# usb register map
Vendor: Texas Instruments
Peripheral module from a debugger description file (folder MSP432E4).
Registers are 8-bit, read-write, no defined reset value unless marked. A register's access mark holds for its fields unless they carry their own. Offsets are as the file gives them; lines under a group give offsets from that group; [hi:lo] are bit positions; {n}, {i} and the like mark numbered series; 'fields as' and 'values as' point back to an identical list; <NAME> marks a mode.

## USB0 — Univeral Serial Bus register offsets
0x00 USB_FADDR — USB Device Functional Address
  [6:0] USB_FADDR — Function Address
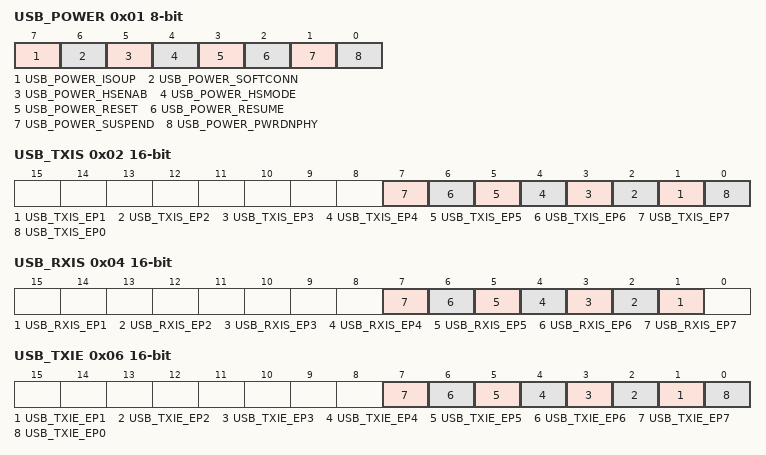
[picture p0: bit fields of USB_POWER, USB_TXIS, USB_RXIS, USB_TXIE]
0x01 USB_POWER
  [7] USB_POWER_ISOUP — Isochronous Update
  [6] USB_POWER_SOFTCONN — Soft Connect/Disconnect
  [5] USB_POWER_HSENAB — High Speed Enable
  [4] USB_POWER_HSMODE — High Speed Enable
  [3] USB_POWER_RESET — RESET Signaling
  [2] USB_POWER_RESUME — RESUME Signaling
  [1] USB_POWER_SUSPEND — SUSPEND Mode
  [0] USB_POWER_PWRDNPHY — Power Down PHY
0x02 USB_TXIS 16-bit ro — USB Transmit Interrupt Status
  [n] USB_TXIS_EP{n} (n=1..7) — TX Endpoint {n} Interrupt
  [0] USB_TXIS_EP0 — TX and RX Endpoint 0 Interrupt
0x04 USB_RXIS 16-bit ro — USB Receive Interrupt Status
  [n] USB_RXIS_EP{n} (n=1..7) — RX Endpoint {n} Interrupt
0x06 USB_TXIE 16-bit — USB Transmit Interrupt Enable
  [n] USB_TXIE_EP{n} (n=1..7) — TX Endpoint {n} Interrupt Enable
  [0] USB_TXIE_EP0 — TX and RX Endpoint 0 Interrupt Enable
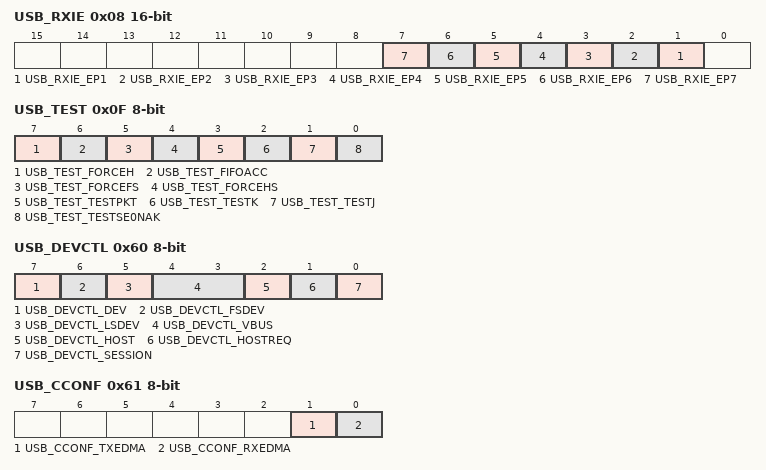
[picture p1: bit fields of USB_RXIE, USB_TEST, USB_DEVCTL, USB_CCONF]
0x08 USB_RXIE 16-bit — USB Receive Interrupt Enable
  [n] USB_RXIE_EP{n} (n=1..7) — RX Endpoint {n} Interrupt Enable
0x0A USB_IS ro — USB General Interrupt Status
  [7] USB_IS_VBUSERR — VBUS Error (OTG only)
  [6] USB_IS_SESREQ — SESSION REQUEST (OTG only)
  [5] USB_IS_DISCON — Session Disconnect (OTG only)
  [4] USB_IS_CONN — Session Connect
  [3] USB_IS_SOF — Start of Frame
  [2] USB_IS_BABBLE — Babble Detected
  [2] USB_IS_RESET — RESET Signaling Detected
  [1] USB_IS_RESUME — RESUME Signaling Detected
  [0] USB_IS_SUSPEND — SUSPEND Signaling Detected
0x0B USB_IE — USB Interrupt Enable
  [7] USB_IE_VBUSERR — Enable VBUS Error Interrupt (OTG only)
  [6] USB_IE_SESREQ — Enable Session Request (OTG only)
  [5] USB_IE_DISCON — Enable Disconnect Interrupt
  [4] USB_IE_CONN — Enable Connect Interrupt
  [3] USB_IE_SOF — Enable Start-of-Frame Interrupt
  [2] USB_IE_BABBLE — Enable Babble Interrupt
  [2] USB_IE_RESET — Enable RESET Interrupt
  [1] USB_IE_RESUME — Enable RESUME Interrupt
  [0] USB_IE_SUSPND — Enable SUSPEND Interrupt
0x0C USB_FRAME 16-bit ro — USB Frame Value
  [10:0] USB_FRAME — Frame Number
0x0E USB_EPIDX — USB Endpoint Index
  [3:0] USB_EPIDX_EPIDX — Endpoint Index
0x0F USB_TEST — USB Test Mode
  [7] USB_TEST_FORCEH — Force Host Mode
  [6] USB_TEST_FIFOACC — FIFO Access
  [5] USB_TEST_FORCEFS — Force Full-Speed Mode
  [4] USB_TEST_FORCEHS — Force High-Speed Mode
  [3] USB_TEST_TESTPKT — Test Packet Mode Enable
  [2] USB_TEST_TESTK — Test_K Mode Enable
  [1] USB_TEST_TESTJ — Test_J Mode Enable
  [0] USB_TEST_TESTSE0NAK — Test_SE0_NAK Test Mode Enable
{0x20+4i} USB_FIFO{i} 32-bit (i=0..7) — USB FIFO Endpoint {i}
  [31:0] USB_FIFO{i}_EPDATA — Endpoint Data
0x60 USB_DEVCTL — USB Device Control
  [7] USB_DEVCTL_DEV — Device Mode (OTG only)
  [6] USB_DEVCTL_FSDEV — Full-Speed Device Detected
  [5] USB_DEVCTL_LSDEV — Low-Speed Device Detected
  [4:3] USB_DEVCTL_VBUS — VBUS Level (OTG only)
    0=USB_DEVCTL_VBUS_NONE (Below SessionEnd); 1=USB_DEVCTL_VBUS_SEND (Above SessionEnd, below AValid); 2=USB_DEVCTL_VBUS_AVALID (Above AValid, below VBUSValid); 3=USB_DEVCTL_VBUS_VALID (Above VBUSValid)
  [2] USB_DEVCTL_HOST — Host Mode
  [1] USB_DEVCTL_HOSTREQ — Host Request (OTG only)
  [0] USB_DEVCTL_SESSION — Session Start/End (OTG only)
0x61 USB_CCONF — USB Common Configuration
  [1] USB_CCONF_TXEDMA — TX Early DMA Enable
  [0] USB_CCONF_RXEDMA — TX Early DMA Enable
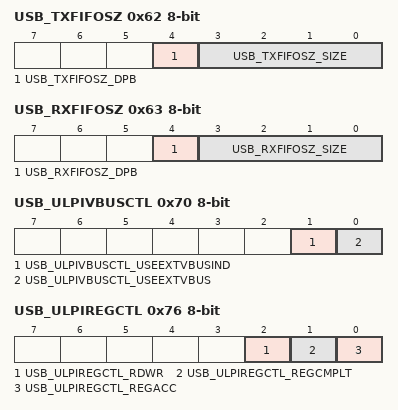
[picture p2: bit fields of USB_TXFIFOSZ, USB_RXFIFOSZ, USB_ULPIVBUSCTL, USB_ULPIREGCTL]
0x62 USB_TXFIFOSZ — USB Transmit Dynamic FIFO Sizing
  [4] USB_TXFIFOSZ_DPB — Double Packet Buffer Support
  [3:0] USB_TXFIFOSZ_SIZE — Max Packet Size
    0=8; 1=16; 2=32; 3=64; 4=128; 5=256; 6=512; 7=1024; 8=2048
0x63 USB_RXFIFOSZ — USB Receive Dynamic FIFO Sizing
  [4] USB_RXFIFOSZ_DPB — Double Packet Buffer Support
  [3:0] USB_RXFIFOSZ_SIZE — Max Packet Size
    0=8; 1=16; 2=32; 3=64; 4=128; 5=256; 6=512; 7=1024; 8=2048
0x64 USB_TXFIFOADD 16-bit — USB Transmit FIFO Start Address
  [8:0] USB_TXFIFOADD_ADDR — Transmit/Receive Start Address
0x66 USB_RXFIFOADD 16-bit — USB Receive FIFO Start Address
  [8:0] USB_RXFIFOADD_ADDR — Transmit/Receive Start Address
0x70 USB_ULPIVBUSCTL — USB ULPI VBUS Control
  [1] USB_ULPIVBUSCTL_USEEXTVBUSIND — Use External VBUS Indicator
  [0] USB_ULPIVBUSCTL_USEEXTVBUS — Use External VBUS
0x74 USB_ULPIREGDATA — USB ULPI Register Data
  [7:0] USB_ULPIREGDATA_REGDATA — Register Data
0x75 USB_ULPIREGADDR — USB ULPI Register Address
  [7:0] USB_ULPIREGADDR_ADDR — Register Address
0x76 USB_ULPIREGCTL — USB ULPI Register Control
  [2] USB_ULPIREGCTL_RDWR — Read/Write Control
  [1] USB_ULPIREGCTL_REGCMPLT — Register Access Complete
  [0] USB_ULPIREGCTL_REGACC — Initiate Register Access
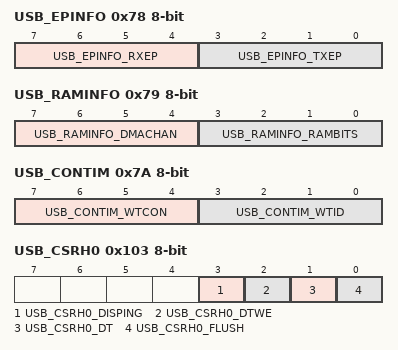
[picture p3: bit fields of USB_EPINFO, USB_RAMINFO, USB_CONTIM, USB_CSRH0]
0x78 USB_EPINFO ro — USB Endpoint Information
  [7:4] USB_EPINFO_RXEP — RX Endpoints
  [3:0] USB_EPINFO_TXEP — TX Endpoints
0x79 USB_RAMINFO ro — USB RAM Information
  [7:4] USB_RAMINFO_DMACHAN — DMA Channels
  [3:0] USB_RAMINFO_RAMBITS — RAM Address Bus Width
0x7A USB_CONTIM — USB Connect Timing
  [7:4] USB_CONTIM_WTCON — Connect Wait
  [3:0] USB_CONTIM_WTID — Wait ID
0x7B USB_VPLEN — USB OTG VBUS Pulse Timing
  [7:0] USB_VPLEN_VPLEN — VBUS Pulse Length
0x7C USB_HSEOF — USB High-Speed Last Transaction to End of Frame Timing
  [7:0] USB_HSEOF_HSEOFG — HIgh-Speed End-of-Frame Gap
0x7D USB_FSEOF — USB Full-Speed Last Transaction to End of Frame Timing
  [7:0] USB_FSEOF_FSEOFG — Full-Speed End-of-Frame Gap
0x7E USB_LSEOF — USB Low-Speed Last Transaction to End of Frame Timing
  [7:0] USB_LSEOF_LSEOFG — Low-Speed End-of-Frame Gap
{0x80+8i} USB_TXFUNCADDR{i} (i=0..7) — USB Transmit Functional Address Endpoint {i}
  [6:0] USB_TXFUNCADDR{i}_ADDR — Device Address
{0x82+8i} USB_TXHUBADDR{i} (i=0..7) — USB Transmit Hub Address Endpoint {i}
  [6:0] USB_TXHUBADDR{i}_ADDR — Hub Address
{0x83+8i} USB_TXHUBPORT{i} (i=0..7) — USB Transmit Hub Port Endpoint {i}
  [6:0] USB_TXHUBPORT{i}_PORT — Hub Port
{0x84+8i} USB_RXFUNCADDR{i} (i=1..7) — USB Receive Functional Address Endpoint {i}
  [6:0] USB_RXFUNCADDR{i}_ADDR — Device Address
{0x86+8i} USB_RXHUBADDR{i} (i=1..7) — USB Receive Hub Address Endpoint {i}
  [6:0] USB_RXHUBADDR{i}_ADDR — Hub Address
{0x87+8i} USB_RXHUBPORT{i} (i=1..7) — USB Receive Hub Port Endpoint {i}
  [6:0] USB_RXHUBPORT{i}_PORT — Hub Port
0x102 USB_CSRL0 wo — USB Control and Status Endpoint 0 Low
  [7] USB_CSRL0_NAKTO — NAK Timeout
  [7] USB_CSRL0_SETENDC — Setup End Clear
  [6] USB_CSRL0_STATUS — STATUS Packet
  [6] USB_CSRL0_RXRDYC — RXRDY Clear
  [5] USB_CSRL0_REQPKT — Request Packet
  [5] USB_CSRL0_STALL — Send Stall
  [4] USB_CSRL0_SETEND — Setup End
  [4] USB_CSRL0_ERROR — Error
  [3] USB_CSRL0_DATAEND — Data End
  [3] USB_CSRL0_SETUP — Setup Packet
  [2] USB_CSRL0_STALLED — Endpoint Stalled
  [1] USB_CSRL0_TXRDY — Transmit Packet Ready
  [0] USB_CSRL0_RXRDY — Receive Packet Ready
0x103 USB_CSRH0 wo — USB Control and Status Endpoint 0 High
  [3] USB_CSRH0_DISPING — PING Disable
  [2] USB_CSRH0_DTWE — Data Toggle Write Enable
  [1] USB_CSRH0_DT — Data Toggle
  [0] USB_CSRH0_FLUSH — Flush FIFO
0x108 USB_COUNT0 ro — USB Receive Byte Count Endpoint 0
  [6:0] USB_COUNT0_COUNT — FIFO Count
0x10A USB_TYPE0 — USB Type Endpoint 0
  [7:6] USB_TYPE0_SPEED — Operating Speed
    1=USB_TYPE0_SPEED_HIGH (High); 2=USB_TYPE0_SPEED_FULL (Full); 3=USB_TYPE0_SPEED_LOW (Low)
0x10B USB_NAKLMT — USB NAK Limit
  [4:0] USB_NAKLMT_NAKLMT — EP0 NAK Limit
{0x100+0x10*i} USB_TXMAXP{i} 16-bit (i=1..7) — USB Maximum Transmit Data Endpoint {i}
  [10:0] USB_TXMAXP{i}_MAXLOAD — Maximum Payload
0x112 USB_TXCSRL1 — USB Transmit Control and Status Endpoint 1 Low
  [7] USB_TXCSRL1_NAKTO — NAK Timeout
  [6] USB_TXCSRL1_CLRDT — Clear Data Toggle
  [5] USB_TXCSRL1_STALLED — Endpoint Stalled
  [4] USB_TXCSRL1_STALL — Send STALL
  [4] USB_TXCSRL1_SETUP — Setup Packet
  [3] USB_TXCSRL1_FLUSH — Flush FIFO
  [2] USB_TXCSRL1_ERROR — Error
  [2] USB_TXCSRL1_UNDRN — Underrun
  [1] USB_TXCSRL1_FIFONE — FIFO Not Empty
  [0] USB_TXCSRL1_TXRDY — Transmit Packet Ready
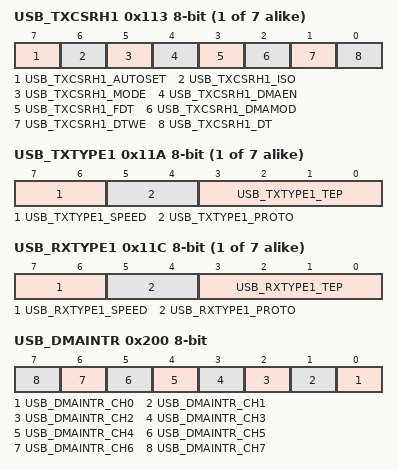
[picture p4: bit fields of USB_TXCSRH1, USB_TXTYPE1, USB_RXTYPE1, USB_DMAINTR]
{0x103+0x10*i} USB_TXCSRH{i} (i=1..7) — USB Transmit Control and Status Endpoint {i} High
  [7] USB_TXCSRH{i}_AUTOSET — Auto Set
  [6] USB_TXCSRH{i}_ISO — Isochronous Transfers
  [5] USB_TXCSRH{i}_MODE — Mode
  [4] USB_TXCSRH{i}_DMAEN — DMA Request Enable
  [3] USB_TXCSRH{i}_FDT — Force Data Toggle
  [2] USB_TXCSRH{i}_DMAMOD — DMA Request Mode
  [1] USB_TXCSRH{i}_DTWE — Data Toggle Write Enable
  [0] USB_TXCSRH{i}_DT — Data Toggle
{0x104+0x10*i} USB_RXMAXP{i} 16-bit (i=1..7) — USB Maximum Receive Data Endpoint {i}
  [10:0] USB_RXMAXP{i}_MAXLOAD — Maximum Payload
0x116 USB_RXCSRL1 — USB Receive Control and Status Endpoint 1 Low
  [7] USB_RXCSRL1_CLRDT — Clear Data Toggle
  [6] USB_RXCSRL1_STALLED — Endpoint Stalled
  [5] USB_RXCSRL1_STALL — Send STALL
  [5] USB_RXCSRL1_REQPKT — Request Packet
  [4] USB_RXCSRL1_FLUSH — Flush FIFO
  [3] USB_RXCSRL1_DATAERR — Data Error
  [3] USB_RXCSRL1_NAKTO — NAK Timeout
  [2] USB_RXCSRL1_OVER — Overrun
  [2] USB_RXCSRL1_ERROR — Error
  [1] USB_RXCSRL1_FULL — FIFO Full
  [0] USB_RXCSRL1_RXRDY — Receive Packet Ready
{0x107+0x10*i} USB_RXCSRH{i} (i=1..6) — USB Receive Control and Status Endpoint {i} High
  [7] USB_RXCSRH{i}_AUTOCL — Auto Clear
  [6] USB_RXCSRH{i}_AUTORQ — Auto Request
  [6] USB_RXCSRH{i}_ISO — Isochronous Transfers
  [5] USB_RXCSRH{i}_DMAEN — DMA Request Enable
  [4] USB_RXCSRH{i}_DISNYET — Disable NYET
  [4] USB_RXCSRH{i}_PIDERR — PID Error
  [3] USB_RXCSRH{i}_DMAMOD — DMA Request Mode
  [2] USB_RXCSRH{i}_DTWE — Data Toggle Write Enable
  [1] USB_RXCSRH{i}_DT — Data Toggle
  [0] USB_RXCSRH{i}_INCOMPRX — Incomplete RX Transmission Status
{0x108+0x10*i} USB_RXCOUNT{i} 16-bit ro (i=1..7) — USB Receive Byte Count Endpoint {i}
  [12:0] USB_RXCOUNT{i}_COUNT — Receive Packet Count
{0x10A+0x10*i} USB_TXTYPE{i} (i=1..7) — USB Host Transmit Configure Type Endpoint {i}
  [7:6] USB_TXTYPE{i}_SPEED — Operating Speed
    0=USB_TXTYPE{i}_SPEED_DFLT (Default); 1=USB_TXTYPE{i}_SPEED_HIGH (High); 2=USB_TXTYPE{i}_SPEED_FULL (Full); 3=USB_TXTYPE{i}_SPEED_LOW (Low)
  [5:4] USB_TXTYPE{i}_PROTO — Protocol
    0=USB_TXTYPE{i}_PROTO_CTRL (Control); 1=USB_TXTYPE{i}_PROTO_ISOC (Isochronous); 2=USB_TXTYPE{i}_PROTO_BULK (Bulk); 3=USB_TXTYPE{i}_PROTO_INT (Interrupt)
  [3:0] USB_TXTYPE{i}_TEP — Target Endpoint Number
0x11B USB_TXINTERVAL1 — USB Host Transmit Interval Endpoint 1
  [7:0] USB_TXINTERVAL1_TXPOLL_NAKLMT — TX Polling / NAK Limit
{0x10C+0x10*i} USB_RXTYPE{i} (i=1..7) — USB Host Configure Receive Type Endpoint {i}
  [7:6] USB_RXTYPE{i}_SPEED — Operating Speed
    0=USB_RXTYPE{i}_SPEED_DFLT (Default); 1=USB_RXTYPE{i}_SPEED_HIGH (High); 2=USB_RXTYPE{i}_SPEED_FULL (Full); 3=USB_RXTYPE{i}_SPEED_LOW (Low)
  [5:4] USB_RXTYPE{i}_PROTO — Protocol
    0=USB_RXTYPE{i}_PROTO_CTRL (Control); 1=USB_RXTYPE{i}_PROTO_ISOC (Isochronous); 2=USB_RXTYPE{i}_PROTO_BULK (Bulk); 3=USB_RXTYPE{i}_PROTO_INT (Interrupt)
  [3:0] USB_RXTYPE{i}_TEP — Target Endpoint Number
{0x10D+0x10*i} USB_RXINTERVAL{i} (i=1..7) — USB Host Receive Polling Interval Endpoint {i}
  [7:0] USB_RXINTERVAL{i}_TXPOLL_NAKLMT — RX Polling / NAK Limit
{0x102+0x10*i} USB_TXCSRL{i} (i=2..5) — USB Transmit Control and Status Endpoint {i} Low
  [7] USB_TXCSRL{i}_NAKTO — NAK Timeout
  [6] USB_TXCSRL{i}_CLRDT — Clear Data Toggle
  [5] USB_TXCSRL{i}_STALLED — Endpoint Stalled
  [4] USB_TXCSRL{i}_SETUP — Setup Packet
  [4] USB_TXCSRL{i}_STALL — Send STALL
  [3] USB_TXCSRL{i}_FLUSH — Flush FIFO
  [2] USB_TXCSRL{i}_ERROR — Error
  [2] USB_TXCSRL{i}_UNDRN — Underrun
  [1] USB_TXCSRL{i}_FIFONE — FIFO Not Empty
  [0] USB_TXCSRL{i}_TXRDY — Transmit Packet Ready
0x126 USB_RXCSRL2 — USB Receive Control and Status Endpoint 2 Low
  [7] USB_RXCSRL2_CLRDT — Clear Data Toggle
  [6] USB_RXCSRL2_STALLED — Endpoint Stalled
  [5] USB_RXCSRL2_REQPKT — Request Packet
  [5] USB_RXCSRL2_STALL — Send STALL
  [4] USB_RXCSRL2_FLUSH — Flush FIFO
  [3] USB_RXCSRL2_DATAERR — Data Error
  [3] USB_RXCSRL2_NAKTO — NAK Timeout
  [2] USB_RXCSRL2_ERROR — Error
  [2] USB_RXCSRL2_OVER — Overrun
  [1] USB_RXCSRL2_FULL — FIFO Full
  [0] USB_RXCSRL2_RXRDY — Receive Packet Ready
0x12B USB_TXINTERVAL2 — USB Host Transmit Interval Endpoint 2
  [7:0] USB_TXINTERVAL2_TXPOLL_NAKLMT — TX Polling/NAK Limit
0x136 USB_RXCSRL3 — USB Receive Control and Status Endpoint 3 Low
  [7] USB_RXCSRL3_CLRDT — Clear Data Toggle
  [6] USB_RXCSRL3_STALLED — Endpoint Stalled
  [5] USB_RXCSRL3_STALL — Send STALL
  [5] USB_RXCSRL3_REQPKT — Request Packet
  [4] USB_RXCSRL3_FLUSH — Flush FIFO
  [3] USB_RXCSRL3_DATAERR — Data Error
  [3] USB_RXCSRL3_NAKTO — NAK Timeout
  [2] USB_RXCSRL3_ERROR — Error
  [2] USB_RXCSRL3_OVER — Overrun
  [1] USB_RXCSRL3_FULL — FIFO Full
  [0] USB_RXCSRL3_RXRDY — Receive Packet Ready
{0x10B+0x10*i} USB_TXINTERVAL{i} (i=3..7) — USB Host Transmit Interval Endpoint {i}
  [7:0] USB_TXINTERVAL{i}_TXPOLL_NAKLMT — TX Polling / NAK Limit
0x146 USB_RXCSRL4 — USB Receive Control and Status Endpoint 4 Low
  [7] USB_RXCSRL4_CLRDT — Clear Data Toggle
  [6] USB_RXCSRL4_STALLED — Endpoint Stalled
  [5] USB_RXCSRL4_STALL — Send STALL
  [5] USB_RXCSRL4_REQPKT — Request Packet
  [4] USB_RXCSRL4_FLUSH — Flush FIFO
  [3] USB_RXCSRL4_NAKTO — NAK Timeout
  [3] USB_RXCSRL4_DATAERR — Data Error
  [2] USB_RXCSRL4_OVER — Overrun
  [2] USB_RXCSRL4_ERROR — Error
  [1] USB_RXCSRL4_FULL — FIFO Full
  [0] USB_RXCSRL4_RXRDY — Receive Packet Ready
0x156 USB_RXCSRL5 — USB Receive Control and Status Endpoint 5 Low
  [7] USB_RXCSRL5_CLRDT — Clear Data Toggle
  [6] USB_RXCSRL5_STALLED — Endpoint Stalled
  [5] USB_RXCSRL5_STALL — Send STALL
  [5] USB_RXCSRL5_REQPKT — Request Packet
  [4] USB_RXCSRL5_FLUSH — Flush FIFO
  [3] USB_RXCSRL5_NAKTO — NAK Timeout
  [3] USB_RXCSRL5_DATAERR — Data Error
  [2] USB_RXCSRL5_ERROR — Error
  [2] USB_RXCSRL5_OVER — Overrun
  [1] USB_RXCSRL5_FULL — FIFO Full
  [0] USB_RXCSRL5_RXRDY — Receive Packet Ready
0x162 USB_TXCSRL6 — USB Transmit Control and Status Endpoint 6 Low
  [7] USB_TXCSRL6_NAKTO — NAK Timeout
  [6] USB_TXCSRL6_CLRDT — Clear Data Toggle
  [5] USB_TXCSRL6_STALLED — Endpoint Stalled
  [4] USB_TXCSRL6_STALL — Send STALL
  [4] USB_TXCSRL6_SETUP — Setup Packet
  [3] USB_TXCSRL6_FLUSH — Flush FIFO
  [2] USB_TXCSRL6_ERROR — Error
  [2] USB_TXCSRL6_UNDRN — Underrun
  [1] USB_TXCSRL6_FIFONE — FIFO Not Empty
  [0] USB_TXCSRL6_TXRDY — Transmit Packet Ready
0x166 USB_RXCSRL6 — USB Receive Control and Status Endpoint 6 Low
  [7] USB_RXCSRL6_CLRDT — Clear Data Toggle
  [6] USB_RXCSRL6_STALLED — Endpoint Stalled
  [5] USB_RXCSRL6_REQPKT — Request Packet
  [5] USB_RXCSRL6_STALL — Send STALL
  [4] USB_RXCSRL6_FLUSH — Flush FIFO
  [3] USB_RXCSRL6_NAKTO — NAK Timeout
  [3] USB_RXCSRL6_DATAERR — Data Error
  [2] USB_RXCSRL6_ERROR — Error
  [2] USB_RXCSRL6_OVER — Overrun
  [1] USB_RXCSRL6_FULL — FIFO Full
  [0] USB_RXCSRL6_RXRDY — Receive Packet Ready
0x172 USB_TXCSRL7 — USB Transmit Control and Status Endpoint 7 Low
  [7] USB_TXCSRL7_NAKTO — NAK Timeout
  [6] USB_TXCSRL7_CLRDT — Clear Data Toggle
  [5] USB_TXCSRL7_STALLED — Endpoint Stalled
  [4] USB_TXCSRL7_STALL — Send STALL
  [4] USB_TXCSRL7_SETUP — Setup Packet
  [3] USB_TXCSRL7_FLUSH — Flush FIFO
  [2] USB_TXCSRL7_ERROR — Error
  [2] USB_TXCSRL7_UNDRN — Underrun
  [1] USB_TXCSRL7_FIFONE — FIFO Not Empty
  [0] USB_TXCSRL7_TXRDY — Transmit Packet Ready
0x176 USB_RXCSRL7 — USB Receive Control and Status Endpoint 7 Low
  [7] USB_RXCSRL7_CLRDT — Clear Data Toggle
  [6] USB_RXCSRL7_STALLED — Endpoint Stalled
  [5] USB_RXCSRL7_REQPKT — Request Packet
  [5] USB_RXCSRL7_STALL — Send STALL
  [4] USB_RXCSRL7_FLUSH — Flush FIFO
  [3] USB_RXCSRL7_DATAERR — Data Error
  [3] USB_RXCSRL7_NAKTO — NAK Timeout
  [2] USB_RXCSRL7_ERROR — Error
  [2] USB_RXCSRL7_OVER — Overrun
  [1] USB_RXCSRL7_FULL — FIFO Full
  [0] USB_RXCSRL7_RXRDY — Receive Packet Ready
0x177 USB_RXCSRH7 — USB Receive Control and Status Endpoint 7 High
  [7] USB_RXCSRH7_AUTOCL — Auto Clear
  [6] USB_RXCSRH7_ISO — Isochronous Transfers
  [6] USB_RXCSRH7_AUTORQ — Auto Request
  [5] USB_RXCSRH7_DMAEN — DMA Request Enable
  [4] USB_RXCSRH7_PIDERR — PID Error
  [4] USB_RXCSRH7_DISNYET — Disable NYET
  [3] USB_RXCSRH7_DMAMOD — DMA Request Mode
  [2] USB_RXCSRH7_DTWE — Data Toggle Write Enable
  [1] USB_RXCSRH7_DT — Data Toggle
  [0] USB_RXCSRH7_INCOMPRX — Incomplete RX Transmission Status
0x200 USB_DMAINTR — USB DMA Interrupt
  [n] USB_DMAINTR_CH{n} (n=0..7) — Channel {n} DMA Interrupt
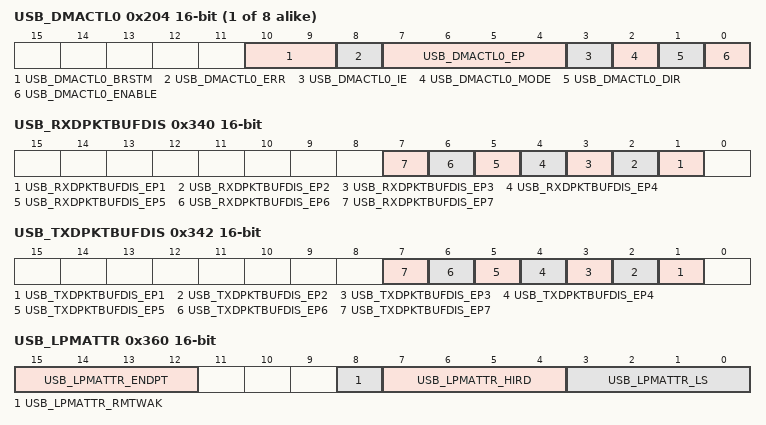
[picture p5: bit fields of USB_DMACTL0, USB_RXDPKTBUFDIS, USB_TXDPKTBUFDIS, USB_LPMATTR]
{0x204+0x10*i} USB_DMACTL{i} 16-bit (i=0..7) — USB DMA Control {i}
  [10:9] USB_DMACTL{i}_BRSTM — Burst Mode
    0=USB_DMACTL{i}_BRSTM_ANY (Bursts of unspecified length); 1=USB_DMACTL{i}_BRSTM_INC4 (INCR4 or unspecified length); 2=USB_DMACTL{i}_BRSTM_INC8 (INCR8, INCR4 or unspecified length); 3=USB_DMACTL{i}_BRSTM_INC16 (INCR16, INCR8, INCR4 or unspecified length)
  [8] USB_DMACTL{i}_ERR — Bus Error Bit
  [7:4] USB_DMACTL{i}_EP — Endpoint number
  [3] USB_DMACTL{i}_IE — DMA Interrupt Enable
  [2] USB_DMACTL{i}_MODE — DMA Transfer Mode
  [1] USB_DMACTL{i}_DIR — DMA Direction
  [0] USB_DMACTL{i}_ENABLE — DMA Transfer Enable
{0x208+0x10*i} USB_DMAADDR{i} 32-bit (i=0..7) — USB DMA Address {i}
  [31:2] USB_DMAADDR{i}_ADDR — DMA Address
{0x20C+0x10*i} USB_DMACOUNT{i} 32-bit (i=0..7)
  [31:2] USB_DMACOUNT{i}_COUNT — DMA Count
{0x300+4i} USB_RQPKTCOUNT{i} 16-bit (i=1..3) — USB Request Packet Count in Block Transfer Endpoint {i}
  [15:0] USB_RQPKTCOUNT{i} — Block Transfer Packet Count
{0x300+4i} USB_RQPKTCOUNT{i} 16-bit (i=4..7) — USB Request Packet Count in Block Transfer Endpoint {i}
  [15:0] USB_RQPKTCOUNT{i}_COUNT — Block Transfer Packet Count
0x340 USB_RXDPKTBUFDIS 16-bit — USB Receive Double Packet Buffer Disable
  [n] USB_RXDPKTBUFDIS_EP{n} (n=1..7) — EP{n} RX Double-Packet Buffer Disable
0x342 USB_TXDPKTBUFDIS 16-bit — USB Transmit Double Packet Buffer Disable
  [n] USB_TXDPKTBUFDIS_EP{n} (n=1..7) — EP{n} TX Double-Packet Buffer Disable
0x344 USB_CTO 16-bit — USB Chirp Timeout
  [15:0] USB_CTO_CCTV — Configurable Chirp Timeout Value
0x346 USB_HHSRTN 16-bit — USB High Speed to UTM Operating Delay
  [15:0] USB_HHSRTN_HHSRTN — HIgh Speed to UTM Operating Delay
0x348 USB_HSBT 16-bit — USB High Speed Time-out Adder
  [3:0] USB_HSBT_HSBT — High Speed Timeout Adder
0x360 USB_LPMATTR 16-bit ro — USB LPM Attributes
  [15:12] USB_LPMATTR_ENDPT — Endpoint
  [8] USB_LPMATTR_RMTWAK — Remote Wake
  [7:4] USB_LPMATTR_HIRD — Host Initiated Resume Duration
  [3:0] USB_LPMATTR_LS — Link State
    1=USB_LPMATTR_LS_L1 (Sleep State (L1))
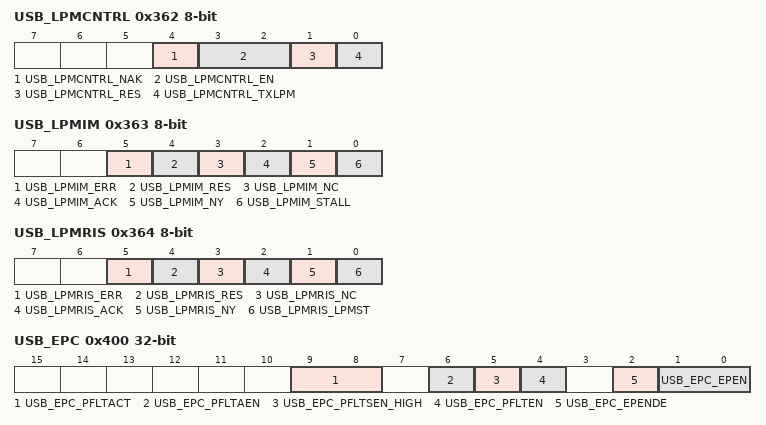
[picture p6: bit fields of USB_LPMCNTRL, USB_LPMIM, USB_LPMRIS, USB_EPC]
0x362 USB_LPMCNTRL ro — USB LPM Control
  [4] USB_LPMCNTRL_NAK — LPM NAK
  [3:2] USB_LPMCNTRL_EN — LPM Enable
    0=USB_LPMCNTRL_EN_NONE (LPM and Extended transactions are not supported. In this case, the USB does not respond to LPM transactions and LPM transactions cause a timeout); 1=USB_LPMCNTRL_EN_EXT (LPM is not supported but extended transactions are supported. In this case, the USB does respond to an LPM transaction with a STALL); 3=USB_LPMCNTRL_EN_LPMEXT (The USB supports LPM extended transactions. In this case, the USB responds with a NYET or an ACK as determined by the value of TXLPM and other conditions)
  [1] USB_LPMCNTRL_RES — LPM Resume
  [0] USB_LPMCNTRL_TXLPM — Transmit LPM Transaction Enable
0x363 USB_LPMIM ro — USB LPM Interrupt Mask
  [5] USB_LPMIM_ERR — LPM Error Interrupt Mask
  [4] USB_LPMIM_RES — LPM Resume Interrupt Mask
  [3] USB_LPMIM_NC — LPM NC Interrupt Mask
  [2] USB_LPMIM_ACK — LPM ACK Interrupt Mask
  [1] USB_LPMIM_NY — LPM NY Interrupt Mask
  [0] USB_LPMIM_STALL — LPM STALL Interrupt Mask
0x364 USB_LPMRIS ro — USB LPM Raw Interrupt Status
  [5] USB_LPMRIS_ERR — LPM Interrupt Status
  [4] USB_LPMRIS_RES — LPM Resume Interrupt Status
  [3] USB_LPMRIS_NC — LPM NC Interrupt Status
  [2] USB_LPMRIS_ACK — LPM ACK Interrupt Status
  [1] USB_LPMRIS_NY — LPM NY Interrupt Status
  [0] USB_LPMRIS_LPMST — LPM STALL Interrupt Status
0x365 USB_LPMFADDR — USB LPM Function Address
  [6:0] USB_LPMFADDR_ADDR — LPM Function Address
0x400 USB_EPC 32-bit — USB External Power Control
  [9:8] USB_EPC_PFLTACT — Power Fault Action
    0=USB_EPC_PFLTACT_UNCHG (Unchanged); 1=USB_EPC_PFLTACT_TRIS (Tristate); 2=USB_EPC_PFLTACT_LOW (Low); 3=USB_EPC_PFLTACT_HIGH (High)
  [6] USB_EPC_PFLTAEN — Power Fault Action Enable
  [5] USB_EPC_PFLTSEN_HIGH — Power Fault Sense
  [4] USB_EPC_PFLTEN — Power Fault Input Enable
  [2] USB_EPC_EPENDE — EPEN Drive Enable
  [1:0] USB_EPC_EPEN — External Power Supply Enable Configuration
    0=USB_EPC_EPEN_LOW (Power Enable Active Low); 1=USB_EPC_EPEN_HIGH (Power Enable Active High); 2=USB_EPC_EPEN_VBLOW (Power Enable High if VBUS Low (OTG only)); 3=USB_EPC_EPEN_VBHIGH (Power Enable High if VBUS High (OTG only))
0x404 USB_EPCRIS 32-bit ro — USB External Power Control Raw Interrupt Status
  [0] USB_EPCRIS_PF — USB Power Fault Interrupt Status
0x408 USB_EPCIM 32-bit — USB External Power Control Interrupt Mask
  [0] USB_EPCIM_PF — USB Power Fault Interrupt Mask
0x40C USB_EPCISC 32-bit — USB External Power Control Interrupt Status and Clear
  [0] USB_EPCISC_PF — USB Power Fault Interrupt Status and Clear
0x410 USB_DRRIS 32-bit ro — USB Device RESUME Raw Interrupt Status
  [0] USB_DRRIS_RESUME — RESUME Interrupt Status
0x414 USB_DRIM 32-bit — USB Device RESUME Interrupt Mask
  [0] USB_DRIM_RESUME — RESUME Interrupt Mask
0x418 USB_DRISC 32-bit wo — USB Device RESUME Interrupt Status and Clear
  [0] USB_DRISC_RESUME — RESUME Interrupt Status and Clear
0x41C USB_GPCS 32-bit — USB General-Purpose Control and Status
  [2:0] USB_GPCS_DEVMOD — Device Mode
    0=USB_GPCS_DEVMOD_OTG (Use USB0VBUS and USB0ID pin); 2=USB_GPCS_DEVMOD_HOST (Force USB0VBUS and USB0ID low); 3=USB_GPCS_DEVMOD_DEV (Force USB0VBUS and USB0ID high); 4=USB_GPCS_DEVMOD_HOSTVBUS (Use USB0VBUS and force USB0ID low); 5=USB_GPCS_DEVMOD_DEVVBUS (Use USB0VBUS and force USB0ID high)
0x430 USB_VDC 32-bit — USB VBUS Droop Control
  [0] USB_VDC_VBDEN — VBUS Droop Enable
0x434 USB_VDCRIS 32-bit ro — USB VBUS Droop Control Raw Interrupt Status
  [0] USB_VDCRIS_VD — VBUS Droop Raw Interrupt Status
0x438 USB_VDCIM 32-bit — USB VBUS Droop Control Interrupt Mask
  [0] USB_VDCIM_VD — VBUS Droop Interrupt Mask
0x43C USB_VDCISC 32-bit — USB VBUS Droop Control Interrupt Status and Clear
  [0] USB_VDCISC_VD — VBUS Droop Interrupt Status and Clear
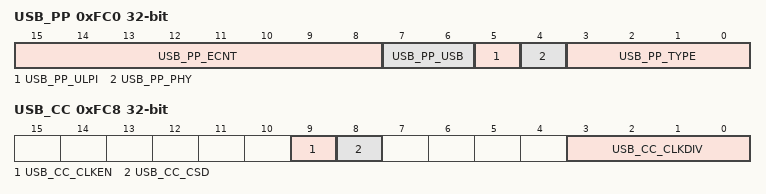
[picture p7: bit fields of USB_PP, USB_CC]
0xFC0 USB_PP 32-bit ro — USB Peripheral Properties
  [15:8] USB_PP_ECNT — Endpoint Count
  [7:6] USB_PP_USB — USB Capability
    1=USB_PP_USB_DEVICE (DEVICE); 2=USB_PP_USB_HOSTDEVICE (HOST); 3=USB_PP_USB_OTG (OTG)
  [5] USB_PP_ULPI — ULPI Present
  [4] USB_PP_PHY — PHY Present
  [3:0] USB_PP_TYPE — Controller Type
    0=The first-generation USB controller; 1=Second-generation USB controller.The controller implemented in post Icestorm devices that use the 3.0 version of the Mentor controller
0xFC4 USB_PC 32-bit — USB Peripheral Configuration
  [16] USB_PC_ULPIEN — ULPI Enable
0xFC8 USB_CC 32-bit ro — USB Clock Configuration
  [9] USB_CC_CLKEN — USB Clock Enable
  [8] USB_CC_CSD — Clock Source/Direction
  [3:0] USB_CC_CLKDIV — PLL Clock Divisor
